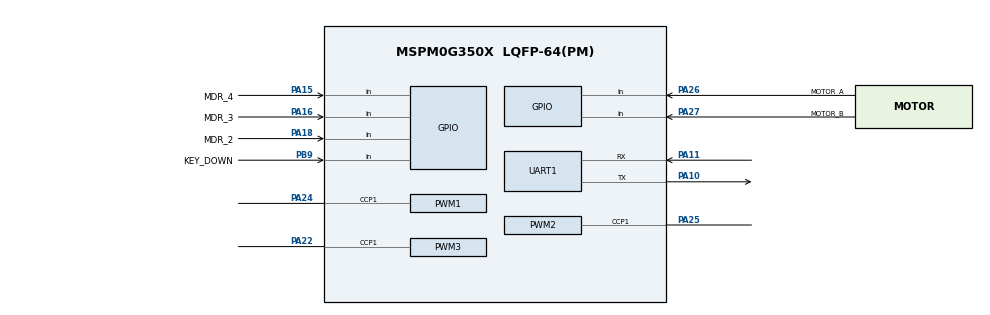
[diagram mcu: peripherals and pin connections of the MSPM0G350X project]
/**
 * @cliArgs --device "MSPM0G350X" --package "LQFP-64(PM)" --part "Default" --product "mspm0_sdk@1.30.00.03"
 * @versions {"tool":"1.19.0+3426"}
 */

/**
 * Import the modules used in this configuration.
 */
const GPIO    = scripting.addModule("/ti/driverlib/GPIO", {}, false);
const GPIO1   = GPIO.addInstance();
const GPIO2   = GPIO.addInstance();
const GPIO3   = GPIO.addInstance();
const GPIO4   = GPIO.addInstance();
const GPIO5   = GPIO.addInstance();
const GPIO6   = GPIO.addInstance();
const PWM     = scripting.addModule("/ti/driverlib/PWM", {}, false);
const PWM1    = PWM.addInstance();
const PWM2    = PWM.addInstance();
const PWM3    = PWM.addInstance();
const SYSCTL  = scripting.addModule("/ti/driverlib/SYSCTL");
const SYSTICK = scripting.addModule("/ti/driverlib/SYSTICK");
const TIMER   = scripting.addModule("/ti/driverlib/TIMER", {}, false);
const TIMER1  = TIMER.addInstance();
const UART    = scripting.addModule("/ti/driverlib/UART", {}, false);
const UART1   = UART.addInstance();

/**
 * Write custom configuration values to the imported modules.
 */
const divider9       = system.clockTree["UDIV"];
divider9.divideValue = 2;

const gate7  = system.clockTree["MFCLKGATE"];
gate7.enable = true;

const multiplier2         = system.clockTree["PLL_QDIV"];
multiplier2.multiplyValue = 4;

const mux4       = system.clockTree["EXHFMUX"];
mux4.inputSelect = "EXHFMUX_XTAL";

const mux8       = system.clockTree["HSCLKMUX"];
mux8.inputSelect = "HSCLKMUX_SYSPLL0";

const mux12       = system.clockTree["SYSPLLMUX"];
mux12.inputSelect = "zSYSPLLMUX_HFCLK";

const pinFunction4        = system.clockTree["HFXT"];
pinFunction4.inputFreq    = 40;
pinFunction4.enable       = true;
pinFunction4.HFXTStartup  = 10;
pinFunction4.HFCLKMonitor = true;

GPIO1.port                                = "PORTA";
GPIO1.$name                               = "MDR";
GPIO1.associatedPins.create(4);
GPIO1.associatedPins[0].direction         = "INPUT";
GPIO1.associatedPins[0].assignedPin       = "17";
GPIO1.associatedPins[0].$name             = "MDR_1";
GPIO1.associatedPins[0].polarity          = "RISE_FALL";
GPIO1.associatedPins[0].internalResistor  = "PULL_UP";
GPIO1.associatedPins[1].$name             = "MDR_2";
GPIO1.associatedPins[1].direction         = "INPUT";
GPIO1.associatedPins[1].assignedPin       = "18";
GPIO1.associatedPins[1].polarity          = "RISE_FALL";
GPIO1.associatedPins[1].internalResistor  = "PULL_UP";
GPIO1.associatedPins[1].pin.$assign       = "PA18";
GPIO1.associatedPins[2].$name             = "MDR_3";
GPIO1.associatedPins[2].direction         = "INPUT";
GPIO1.associatedPins[2].assignedPin       = "16";
GPIO1.associatedPins[2].polarity          = "RISE_FALL";
GPIO1.associatedPins[2].internalResistor  = "PULL_UP";
GPIO1.associatedPins[2].pin.$assign       = "PA16";
GPIO1.associatedPins[3].$name             = "MDR_4";
GPIO1.associatedPins[3].direction         = "INPUT";
GPIO1.associatedPins[3].assignedPin       = "15";
GPIO1.associatedPins[3].internalResistor  = "PULL_UP";
GPIO1.associatedPins[3].interruptPriority = "2";
GPIO1.associatedPins[3].polarity          = "RISE_FALL";
GPIO1.associatedPins[3].pin.$assign       = "PA15";

const Board = scripting.addModule("/ti/driverlib/Board", {}, false);

GPIO2.port                                = "PORTA";
GPIO2.$name                               = "MOTOR";
GPIO2.associatedPins.create(2);
GPIO2.associatedPins[0].direction         = "INPUT";
GPIO2.associatedPins[0].polarity          = "RISE";
GPIO2.associatedPins[0].$name             = "MOTOR_A";
GPIO2.associatedPins[0].interruptEn       = true;
GPIO2.associatedPins[0].interruptPriority = "0";
GPIO2.associatedPins[0].assignedPin       = "26";
GPIO2.associatedPins[0].pin.$assign       = "PA26";
GPIO2.associatedPins[1].$name             = "MOTOR_B";
GPIO2.associatedPins[1].direction         = "INPUT";
GPIO2.associatedPins[1].polarity          = "RISE";
GPIO2.associatedPins[1].interruptEn       = true;
GPIO2.associatedPins[1].interruptPriority = "0";
GPIO2.associatedPins[1].assignedPin       = "27";
GPIO2.associatedPins[1].pin.$assign       = "PA27";

GPIO3.port                           = "PORTA";
GPIO3.$name                          = "WS2812";
GPIO3.associatedPins[0].assignedPin  = "28";
GPIO3.associatedPins[0].initialValue = "SET";
GPIO3.associatedPins[0].ioStructure  = "HD";
GPIO3.associatedPins[0].$name        = "LED_PIN";

GPIO4.port                               = "PORTB";
GPIO4.$name                              = "KEY";
GPIO4.associatedPins.create(4);
GPIO4.associatedPins[0].direction        = "INPUT";
GPIO4.associatedPins[0].$name            = "KEY_UP";
GPIO4.associatedPins[0].internalResistor = "PULL_UP";
GPIO4.associatedPins[0].assignedPin      = "24";
GPIO4.associatedPins[1].$name            = "KEY_DOWN";
GPIO4.associatedPins[1].direction        = "INPUT";
GPIO4.associatedPins[1].assignedPin      = "9";
GPIO4.associatedPins[1].internalResistor = "PULL_UP";
GPIO4.associatedPins[1].pin.$assign      = "PB9";
GPIO4.associatedPins[2].$name            = "KEY_LEFT";
GPIO4.associatedPins[2].direction        = "INPUT";
GPIO4.associatedPins[2].internalResistor = "PULL_UP";
GPIO4.associatedPins[2].assignedPin      = "8";
GPIO4.associatedPins[3].$name            = "KEY_RIGHT";
GPIO4.associatedPins[3].direction        = "INPUT";
GPIO4.associatedPins[3].assignedPin      = "20";
GPIO4.associatedPins[3].internalResistor = "PULL_UP";

GPIO5.$name                         = "OLED_A";
GPIO5.port                          = "PORTA";
GPIO5.associatedPins.create(2);
GPIO5.associatedPins[0].$name       = "SPI_PICO";
GPIO5.associatedPins[0].assignedPin = "9";
GPIO5.associatedPins[1].$name       = "SPI_CS0";
GPIO5.associatedPins[1].assignedPin = "8";

GPIO6.$name                         = "OLED_B";
GPIO6.port                          = "PORTB";
GPIO6.associatedPins.create(3);
GPIO6.associatedPins[0].$name       = "SPI_SCK";
GPIO6.associatedPins[0].assignedPin = "18";
GPIO6.associatedPins[1].$name       = "SPI_PIN1";
GPIO6.associatedPins[1].assignedPin = "2";
GPIO6.associatedPins[2].$name       = "SPI_PIN2";
GPIO6.associatedPins[2].assignedPin = "3";

PWM1.timerStartTimer                    = true;
PWM1.clockDivider                       = 8;
PWM1.$name                              = "PWM_MOTOR_1";
PWM1.timerCount                         = 500;
PWM1.ccIndex                            = [1];
PWM1.peripheral.$assign                 = "TIMG7";
PWM1.peripheral.ccp1Pin.$assign         = "PA24";
PWM1.ccp1PinConfig.direction            = scripting.forceWrite("OUTPUT");
PWM1.ccp1PinConfig.hideOutputInversion  = scripting.forceWrite(false);
PWM1.ccp1PinConfig.onlyInternalResistor = scripting.forceWrite(false);
PWM1.ccp1PinConfig.passedPeripheralType = scripting.forceWrite("Digital");
PWM1.ccp1PinConfig.$name                = "ti_driverlib_gpio_GPIOPinGeneric2";
PWM1.PWM_CHANNEL_1.$name                = "ti_driverlib_pwm_PWMTimerCC0";

PWM2.$name                              = "PWM_MOTOR_2";
PWM2.ccIndex                            = [1];
PWM2.timerStartTimer                    = true;
PWM2.timerCount                         = 500;
PWM2.clockDivider                       = 8;
PWM2.peripheral.$assign                 = "TIMG12";
PWM2.peripheral.ccp1Pin.$assign         = "PA25";
PWM2.ccp1PinConfig.direction            = scripting.forceWrite("OUTPUT");
PWM2.ccp1PinConfig.hideOutputInversion  = scripting.forceWrite(false);
PWM2.ccp1PinConfig.onlyInternalResistor = scripting.forceWrite(false);
PWM2.ccp1PinConfig.passedPeripheralType = scripting.forceWrite("Digital");
PWM2.ccp1PinConfig.$name                = "ti_driverlib_gpio_GPIOPinGeneric8";
PWM2.PWM_CHANNEL_1.$name                = "ti_driverlib_pwm_PWMTimerCC1";

PWM3.$name                              = "PWM_TEST";
PWM3.ccIndex                            = [1];
PWM3.clockDivider                       = 8;
PWM3.timerCount                         = 500;
PWM3.peripheral.$assign                 = "TIMG6";
PWM3.peripheral.ccp1Pin.$assign         = "PA22";
PWM3.ccp1PinConfig.direction            = scripting.forceWrite("OUTPUT");
PWM3.ccp1PinConfig.hideOutputInversion  = scripting.forceWrite(false);
PWM3.ccp1PinConfig.onlyInternalResistor = scripting.forceWrite(false);
PWM3.ccp1PinConfig.passedPeripheralType = scripting.forceWrite("Digital");
PWM3.ccp1PinConfig.$name                = "ti_driverlib_gpio_GPIOPinGeneric3";
PWM3.PWM_CHANNEL_1.$name                = "ti_driverlib_pwm_PWMTimerCC2";

SYSCTL.forceDefaultClkConfig = true;
SYSCTL.clockTreeEn           = true;

SYSTICK.interruptEnable   = true;
SYSTICK.interruptPriority = "0";
SYSTICK.periodEnable      = true;
SYSTICK.systickEnable     = true;
SYSTICK.period            = 800;

TIMER1.$name              = "TIMER_SCAN";
TIMER1.timerClkDiv        = 8;
TIMER1.timerClkPrescale   = 10;
TIMER1.timerMode          = "PERIODIC";
TIMER1.timerStartTimer    = true;
TIMER1.interrupts         = ["ZERO"];
TIMER1.timerPeriod        = "20ms";
TIMER1.peripheral.$assign = "TIMA0";

UART1.$name                    = "UART_0";
UART1.uartClkSrc               = "MFCLK";
UART1.enabledInterrupts        = ["RX"];
UART1.peripheral.$assign       = "UART0";
UART1.peripheral.rxPin.$assign = "PA11";
UART1.peripheral.txPin.$assign = "PA10";
UART1.txPinConfig.$name        = "ti_driverlib_gpio_GPIOPinGeneric0";
UART1.rxPinConfig.$name        = "ti_driverlib_gpio_GPIOPinGeneric1";

/**
 * Pinmux solution for unlocked pins/peripherals. This ensures that minor changes to the automatic solver in a future
 * version of the tool will not impact the pinmux you originally saw.  These lines can be completely deleted in order to
 * re-solve from scratch.
 */
pinFunction4.peripheral.$suggestSolution           = "SYSCTL";
pinFunction4.peripheral.hfxInPin.$suggestSolution  = "PA5";
pinFunction4.peripheral.hfxOutPin.$suggestSolution = "PA6";
GPIO1.associatedPins[0].pin.$suggestSolution       = "PA17";
Board.peripheral.$suggestSolution                  = "DEBUGSS";
Board.peripheral.swclkPin.$suggestSolution         = "PA20";
Board.peripheral.swdioPin.$suggestSolution         = "PA19";
GPIO3.associatedPins[0].pin.$suggestSolution       = "PA28";
GPIO4.associatedPins[0].pin.$suggestSolution       = "PB24";
GPIO4.associatedPins[2].pin.$suggestSolution       = "PB8";
GPIO4.associatedPins[3].pin.$suggestSolution       = "PB20";
GPIO5.associatedPins[0].pin.$suggestSolution       = "PA9";
GPIO5.associatedPins[1].pin.$suggestSolution       = "PA8";
GPIO6.associatedPins[0].pin.$suggestSolution       = "PB18";
GPIO6.associatedPins[1].pin.$suggestSolution       = "PB2";
GPIO6.associatedPins[2].pin.$suggestSolution       = "PB3";
